# STM32H7B3x register map
File version: 2.2
CPU: CM7 r0p1, little endian, MPU, FPU, 4 interrupt priority bits
Registers are 32-bit, read-write, reset 0x0 unless marked. A register's access mark holds for its fields unless they carry their own. Offsets are from the block's base; [hi:lo] are bit positions; {n}, {i} and the like mark numbered series.

## DELAY_Block_SDMMC1
Base 0x52008000
Same registers: DELAY_Block_SDMMC2 0x48022800, Delay_Block_OCTOSPI1 0x52006000, Delay_Block_OCTOSPI2 0x5200B000
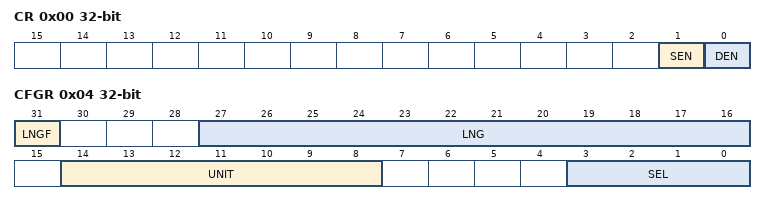
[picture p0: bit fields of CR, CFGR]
0x00 CR — DLYB control register
  [1] SEN — Sampler length enable bit
  [0] DEN — Delay block enable bit
0x04 CFGR — DLYB configuration register
  [31] LNGF — Length valid flag
  [27:16] LNG — Delay line length value
  [14:8] UNIT — Delay Defines the delay of a Unit delay cell
  [3:0] SEL — Select the phase for the Output clock

## FPU — Floting point unit
Base 0xE000EF34
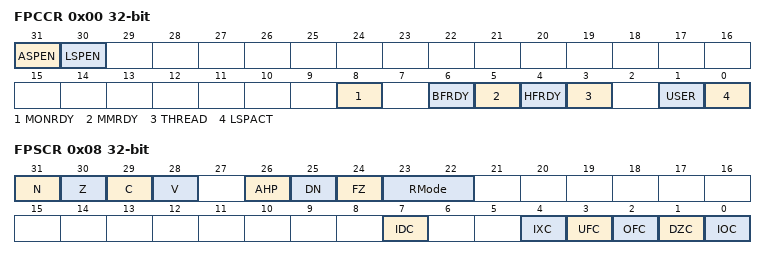
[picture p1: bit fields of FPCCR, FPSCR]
0x00 FPCCR — Floating-point context control register
  [31] ASPEN, [30] LSPEN, [8] MONRDY, [6] BFRDY, [5] MMRDY, [4] HFRDY, [3] THREAD, [1] USER, [0] LSPACT
0x04 FPCAR — Floating-point context address register
  [31:3] ADDRESS — Location of unpopulated floating-point
0x08 FPSCR — Floating-point status control register
  [31] N — Negative condition code flag
  [30] Z — Zero condition code flag
  [29] C — Carry condition code flag
  [28] V — Overflow condition code flag
  [26] AHP — Alternative half-precision control bit
  [25] DN — Default NaN mode control bit
  [24] FZ — Flush-to-zero mode control bit:
  [23:22] RMode — Rounding Mode control field
  [7] IDC — Input denormal cumulative exception bit.
  [4] IXC — Inexact cumulative exception bit
  [3] UFC — Underflow cumulative exception bit
  [2] OFC — Overflow cumulative exception bit
  [1] DZC — Division by zero cumulative exception bit.
  [0] IOC — Invalid operation cumulative exception bit

## FPU_CPACR — Floating point unit CPACR
Base 0xE000ED88
0x00 CPACR — Coprocessor access control register
  [23:20] CP

## HASH — Hash processor
Base 0x48021400
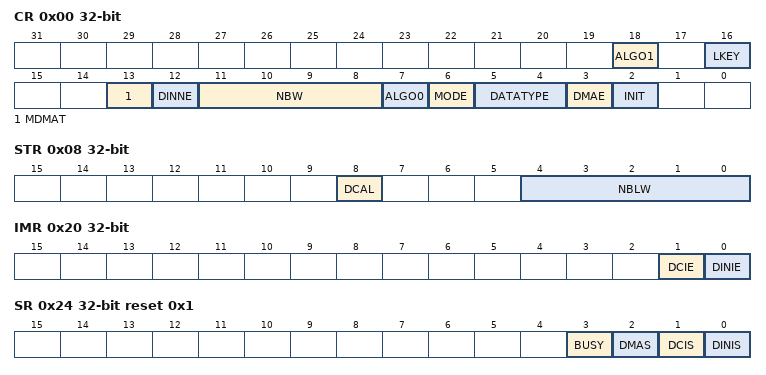
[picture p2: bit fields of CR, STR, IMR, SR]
0x00 CR access per field — control register
  [18] ALGO1 rw — ALGO
  [16] LKEY rw — Long key selection
  [13] MDMAT rw — Multiple DMA Transfers
  [12] DINNE ro — DIN not empty
  [11:8] NBW ro — Number of words already pushed
  [7] ALGO0 rw — Algorithm selection
  [6] MODE rw — Mode selection
  [5:4] DATATYPE rw — Data type selection
  [3] DMAE rw — DMA enable
  [2] INIT wo — Initialize message digest calculation
0x04 DIN — data input register
  [31:0] DATAIN — Data input
0x08 STR access per field — start register
  [8] DCAL wo — Digest calculation
  [4:0] NBLW rw — Number of valid bits in the last word of the message
{0xC+4i} HR{i} (i=0..4) ro — digest registers
  [31:0] H — H0
0x20 IMR — interrupt enable register
  [1] DCIE — Digest calculation completion interrupt enable
  [0] DINIE — Data input interrupt enable
0x24 SR access per field reset 0x1 — status register
  [3] BUSY ro — Busy bit
  [2] DMAS ro — DMA Status
  [1] DCIS rw — Digest calculation completion interrupt status
  [0] DINIS rw — Data input interrupt status
{0xF8+4i} CSR{i} (i=0..53) — context swap registers
  [31:0] CSR — CSR0
{0x310+4i} HASH_HR{i} (i=0..7) ro — HASH digest register
  [31:0] H — H0

## HRTIM_Master — High Resolution Timer: Master Timers
Base 0x40017400
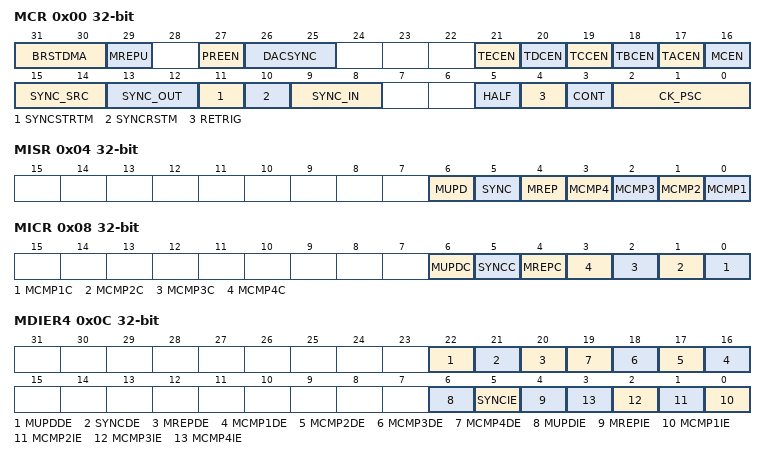
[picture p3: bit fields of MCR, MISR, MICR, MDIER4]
0x00 MCR — Master Timer Control Register
  [31:30] BRSTDMA — Burst DMA Update
  [29] MREPU — Master Timer Repetition update
  [27] PREEN — Preload enable
  [26:25] DACSYNC — AC Synchronization
  [21] TECEN — Timer E counter enable
  [20] TDCEN — Timer D counter enable
  [19] TCCEN — Timer C counter enable
  [18] TBCEN — Timer B counter enable
  [17] TACEN — Timer A counter enable
  [16] MCEN — Master Counter enable
  [15:14] SYNC_SRC — Synchronization source
  [13:12] SYNC_OUT — Synchronization output
  [11] SYNCSTRTM — Synchronization Starts Master
  [10] SYNCRSTM — Synchronization Resets Master
  [9:8] SYNC_IN — ynchronization input
  [5] HALF — Half mode enable
  [4] RETRIG — Master Re-triggerable mode
  [3] CONT — Master Continuous mode
  [2:0] CK_PSC — HRTIM Master Clock prescaler
0x04 MISR ro — Master Timer Interrupt Status Register
  [6] MUPD — Master Update Interrupt Flag
  [5] SYNC — Sync Input Interrupt Flag
  [4] MREP — Master Repetition Interrupt Flag
  [n-1] MCMP{n} (n=1..4) — Master Compare {n} Interrupt Flag
0x08 MICR wo — Master Timer Interrupt Clear Register
  [6] MUPDC — Master update Interrupt flag clear
  [5] SYNCC — Sync Input Interrupt flag clear
  [4] MREPC — Repetition Interrupt flag clear
  [n-1] MCMP{n}C (n=1..4) — Master Compare {n} Interrupt flag clear
0x0C MDIER4
  [22] MUPDDE, [21] SYNCDE, [20] MREPDE, [n+15] MCMP{n}DE (n=1..4), [6] MUPDIE, [5] SYNCIE, [4] MREPIE, [n-1] MCMP{n}IE (n=1..4)
0x10 MCNTR — Master Timer Counter Register
  [15:0] MCNT — Counter value
0x14 MPER reset 0xFFFF — Master Timer Period Register
  [15:0] MPER — Master Timer Period value
0x18 MREP — Master Timer Repetition Register
  [7:0] MREP — Master Timer Repetition counter value
0x1C MCMP1R — Master Timer Compare 1 Register
  [15:0] MCMP1 — Master Timer Compare 1 value
{0x1C+4i} MCMP{i}R (i=2..4) — Master Timer Compare {i} Register
  [15:0] MCMP{i} — Master Timer Compare {i} value
